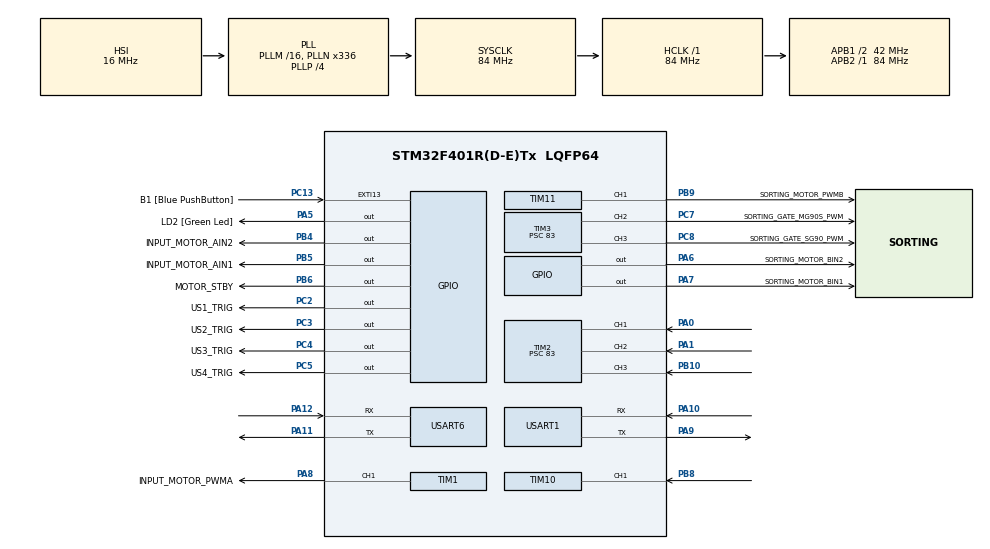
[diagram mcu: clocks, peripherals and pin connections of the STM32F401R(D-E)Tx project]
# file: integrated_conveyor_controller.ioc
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Dma.Request0=USART1_RX
Dma.Request1=USART1_TX
Dma.Request2=USART6_RX
Dma.Request3=USART6_TX
Dma.USART1_RX.0.Direction=DMA_PERIPH_TO_MEMORY
Dma.USART1_RX.0.FIFOMode=DMA_FIFOMODE_DISABLE
Dma.USART1_RX.0.Instance=DMA2_Stream5
Dma.USART1_RX.0.MemDataAlignment=DMA_MDATAALIGN_BYTE
Dma.USART1_RX.0.MemInc=DMA_MINC_ENABLE
Dma.USART1_RX.0.Mode=DMA_CIRCULAR
Dma.USART1_RX.0.PeriphDataAlignment=DMA_PDATAALIGN_BYTE
Dma.USART1_RX.0.PeriphInc=DMA_PINC_DISABLE
Dma.USART1_RX.0.Priority=DMA_PRIORITY_HIGH
Dma.USART1_TX.1.Direction=DMA_MEMORY_TO_PERIPH
Dma.USART1_TX.1.FIFOMode=DMA_FIFOMODE_DISABLE
Dma.USART1_TX.1.Instance=DMA2_Stream7
Dma.USART1_TX.1.MemDataAlignment=DMA_MDATAALIGN_BYTE
Dma.USART1_TX.1.MemInc=DMA_MINC_ENABLE
Dma.USART1_TX.1.Mode=DMA_NORMAL
Dma.USART1_TX.1.PeriphDataAlignment=DMA_PDATAALIGN_BYTE
Dma.USART1_TX.1.PeriphInc=DMA_PINC_DISABLE
Dma.USART1_TX.1.Priority=DMA_PRIORITY_MEDIUM
Dma.USART6_RX.2.Direction=DMA_PERIPH_TO_MEMORY
Dma.USART6_RX.2.FIFOMode=DMA_FIFOMODE_DISABLE
Dma.USART6_RX.2.Instance=DMA2_Stream1
Dma.USART6_RX.2.MemDataAlignment=DMA_MDATAALIGN_BYTE
Dma.USART6_RX.2.MemInc=DMA_MINC_ENABLE
Dma.USART6_RX.2.Mode=DMA_CIRCULAR
Dma.USART6_RX.2.PeriphDataAlignment=DMA_PDATAALIGN_BYTE
Dma.USART6_RX.2.PeriphInc=DMA_PINC_DISABLE
Dma.USART6_RX.2.Priority=DMA_PRIORITY_HIGH
Dma.USART6_TX.3.Direction=DMA_MEMORY_TO_PERIPH
Dma.USART6_TX.3.FIFOMode=DMA_FIFOMODE_DISABLE
Dma.USART6_TX.3.Instance=DMA2_Stream6
Dma.USART6_TX.3.MemDataAlignment=DMA_MDATAALIGN_BYTE
Dma.USART6_TX.3.MemInc=DMA_MINC_ENABLE
Dma.USART6_TX.3.Mode=DMA_NORMAL
Dma.USART6_TX.3.PeriphDataAlignment=DMA_PDATAALIGN_BYTE
Dma.USART6_TX.3.PeriphInc=DMA_PINC_DISABLE
Dma.USART6_TX.3.Priority=DMA_PRIORITY_MEDIUM
FREERTOS.Tasks01=CommRxTask,32,512,StartCommRxTask,As weak,NULL,Dynamic,NULL,NULL;InputControlTask,24,512,StartInputControlTask,As weak,NULL,Dynamic,NULL,NULL;SortingControlTask,24,512,StartSortingControlTask,As weak,NULL,Dynamic,NULL,NULL;SafetyTask,40,512,StartSafetyTask,As weak,NULL,Dynamic,NULL,NULL;CommTxTask,32,512,StartCommTxTask,As weak,NULL,Dynamic,NULL,NULL;SensorTask,24,512,StartSensorTask,As weak,NULL,Dynamic,NULL,NULL;HealthTask,16,512,StartHealthTask,As weak,NULL,Dynamic,NULL,NULL
FREERTOS.configMAX_TASK_NAME_LEN=24
FREERTOS.configTOTAL_HEAP_SIZE=32768
Mcu.Family=STM32F4
Mcu.Name=STM32F401R(D-E)Tx
Mcu.Package=LQFP64
NVIC.DMA2_Stream1_IRQn=true\:5\:0\:false\:false\:true\:true\:false\:true\:true
NVIC.DMA2_Stream5_IRQn=true\:5\:0\:false\:false\:true\:true\:false\:true\:true
NVIC.DMA2_Stream6_IRQn=true\:6\:0\:true\:false\:true\:true\:false\:true\:true
NVIC.DMA2_Stream7_IRQn=true\:6\:0\:true\:false\:true\:true\:false\:true\:true
NVIC.PriorityGroup=NVIC_PRIORITYGROUP_4
NVIC.TIM1_UP_TIM10_IRQn=true\:5\:0\:false\:false\:true\:true\:true\:true\:true
NVIC.TIM2_IRQn=true\:5\:0\:false\:false\:true\:true\:true\:true\:true
NVIC.TIM5_IRQn=true\:0\:0\:false\:false\:true\:false\:false\:true\:true
NVIC.TimeBase=TIM5_IRQn
NVIC.TimeBaseIP=TIM5
NVIC.USART1_IRQn=true\:5\:0\:false\:false\:true\:true\:true\:true\:true
NVIC.USART6_IRQn=true\:5\:0\:false\:false\:true\:true\:true\:true\:true
PA0-WKUP.GPIO_PuPd=GPIO_PULLDOWN
PA0-WKUP.Signal=S_TIM2_CH1_ETR
PA1.GPIO_PuPd=GPIO_PULLDOWN
PA1.Signal=S_TIM2_CH2
PA10.Mode=Asynchronous
PA10.Signal=USART1_RX
PA11.Mode=Asynchronous
PA11.Signal=USART6_TX
PA12.Mode=Asynchronous
PA12.Signal=USART6_RX
PA13.GPIO_Label=TMS
PA13.Mode=Serial_Wire
PA13.Signal=SYS_JTMS-SWDIO
PA14.GPIO_Label=TCK
PA14.Mode=Serial_Wire
PA14.Signal=SYS_JTCK-SWCLK
PA5.GPIO_Label=LD2 [Green Led]
PA5.GPIO_Mode=GPIO_MODE_OUTPUT_PP
PA5.GPIO_PuPd=GPIO_NOPULL
PA5.GPIO_Speed=GPIO_SPEED_FREQ_LOW
PA5.Signal=GPIO_Output
PA6.GPIO_Label=SORTING_MOTOR_BIN2
PA6.Signal=GPIO_Output
PA7.GPIO_Label=SORTING_MOTOR_BIN1
PA7.Signal=GPIO_Output
PA8.GPIO_Label=INPUT_MOTOR_PWMA
PA8.Signal=S_TIM1_CH1
PA9.Mode=Asynchronous
PA9.Signal=USART1_TX
PB10.GPIO_PuPd=GPIO_PULLDOWN
PB10.Signal=S_TIM2_CH3
PB3.GPIO_Label=SWO
PB3.Signal=SYS_JTDO-SWO
PB4.GPIO_Label=INPUT_MOTOR_AIN2
PB4.Signal=GPIO_Output
PB5.GPIO_Label=INPUT_MOTOR_AIN1
PB5.Signal=GPIO_Output
PB6.GPIO_Label=MOTOR_STBY
PB6.Signal=GPIO_Output
PB8.GPIO_PuPd=GPIO_PULLDOWN
PB8.Signal=S_TIM10_CH1
PB9.GPIO_Label=SORTING_MOTOR_PWMB
PB9.Signal=S_TIM11_CH1
PC13-ANTI_TAMP.GPIO_Label=B1 [Blue PushButton]
PC13-ANTI_TAMP.GPIO_ModeDefaultEXTI=GPIO_MODE_IT_FALLING
PC13-ANTI_TAMP.GPIO_PuPd=GPIO_NOPULL
PC13-ANTI_TAMP.Signal=GPXTI13
PC14-OSC32_IN.Signal=RCC_OSC32_IN
PC15-OSC32_OUT.Signal=RCC_OSC32_OUT
PC2.GPIO_Label=US1_TRIG
PC2.Signal=GPIO_Output
PC3.GPIO_Label=US2_TRIG
PC3.Signal=GPIO_Output
PC4.GPIO_Label=US3_TRIG
PC4.Signal=GPIO_Output
PC5.GPIO_Label=US4_TRIG
PC5.Signal=GPIO_Output
PC7.GPIO_Label=SORTING_GATE_MG90S_PWM
PC7.Signal=S_TIM3_CH2
PC8.GPIO_Label=SORTING_GATE_SG90_PWM
PC8.Signal=S_TIM3_CH3
PH0\ -\ OSC_IN.Mode=HSE-External-Clock-Source
PH0\ -\ OSC_IN.Signal=RCC_OSC_IN
PH1\ -\ OSC_OUT.Mode=HSE-External-Clock-Source
PH1\ -\ OSC_OUT.Signal=RCC_OSC_OUT
ProjectManager.HeapSize=0x200
ProjectManager.StackSize=0x400
ProjectManager.TargetToolchain=STM32CubeIDE
RCC.AHBFreq_Value=84000000
RCC.APB1CLKDivider=RCC_HCLK_DIV2
RCC.APB1Freq_Value=42000000
RCC.APB1TimFreq_Value=84000000
RCC.APB2Freq_Value=84000000
RCC.APB2TimFreq_Value=84000000
RCC.CortexFreq_Value=84000000
RCC.HCLKFreq_Value=84000000
RCC.HSE_VALUE=8000000
RCC.HSI_VALUE=16000000
RCC.LSE_VALUE=32768
RCC.PLLN=336
RCC.PLLP=RCC_PLLP_DIV4
RCC.PLLQ=7
RCC.SYSCLKFreq_VALUE=84000000
RCC.SYSCLKSource=RCC_SYSCLKSOURCE_PLLCLK
RCC.VCOOutputFreq_Value=336000000
SH.S_TIM10_CH1.0=TIM10_CH1,Input_Capture1_from_TI1
SH.S_TIM11_CH1.0=TIM11_CH1,PWM Generation1 CH1
SH.S_TIM1_CH1.0=TIM1_CH1,PWM Generation1 CH1
SH.S_TIM2_CH1_ETR.0=TIM2_CH1,Input_Capture1_from_TI1
SH.S_TIM2_CH2.0=TIM2_CH2,Input_Capture2_from_TI2
SH.S_TIM2_CH3.0=TIM2_CH3,Input_Capture3_from_TI3
SH.S_TIM3_CH2.0=TIM3_CH2,PWM Generation2 CH2
SH.S_TIM3_CH3.0=TIM3_CH3,PWM Generation3 CH3
TIM1.Channel-PWM\ Generation1\ CH1=TIM_CHANNEL_1
TIM1.Period=4199
TIM10.Channel=TIM_CHANNEL_1
TIM10.Prescaler=83
TIM11.Channel=TIM_CHANNEL_1
TIM11.Period=4199
TIM2.Channel-Input_Capture1_from_TI1=TIM_CHANNEL_1
TIM2.Channel-Input_Capture2_from_TI2=TIM_CHANNEL_2
TIM2.Channel-Input_Capture3_from_TI3=TIM_CHANNEL_3
TIM2.Prescaler=83
TIM3.Channel-PWM\ Generation2\ CH2=TIM_CHANNEL_2
TIM3.Channel-PWM\ Generation3\ CH3=TIM_CHANNEL_3
TIM3.Period=19999
TIM3.Prescaler=83
USART1.VirtualMode=VM_ASYNC
USART6.VirtualMode=VM_ASYNC
VP_FREERTOS_VS_CMSIS_V2.Mode=CMSIS_V2
VP_SYS_VS_tim5.Mode=TIM5
VP_TIM10_VS_ClockSourceINT.Mode=Enable_Timer
VP_TIM11_VS_ClockSourceINT.Mode=Enable_Timer
board=NUCLEO-F401RE

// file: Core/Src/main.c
/* USER CODE BEGIN Header */
/**
  ******************************************************************************
  * @file           : main.c
  * @brief          : Main program body
  ******************************************************************************
  * @attention
  *
  * Copyright (c) 2026 STMicroelectronics.
  * All rights reserved.
  *
  * This software is licensed under terms that can be found in the LICENSE file
  * in the root directory of this software component.
  * If no LICENSE file comes with this software, it is provided AS-IS.
  *
  ******************************************************************************
  */
/* USER CODE END Header */
#include "main.h"
#include "cmsis_os.h"
#include "dma.h"
#include "tim.h"
#include "usart.h"
#include "gpio.h"

void SystemClock_Config(void);
void MX_FREERTOS_Init(void);

int main(void)
{

  /* MCU Configuration--------------------------------------------------------*/

  /* Reset of all peripherals, Initializes the Flash interface and the Systick. */
  HAL_Init();

  /* Configure the system clock */
  SystemClock_Config();

  /* Initialize all configured peripherals */
  MX_GPIO_Init();
  MX_DMA_Init();
  MX_USART1_UART_Init();
  MX_USART6_UART_Init();
  MX_TIM2_Init();
  MX_TIM10_Init();
  MX_TIM1_Init();
  MX_TIM3_Init();
  MX_TIM11_Init();

  /* Init scheduler */
  osKernelInitialize();  /* Call init function for freertos objects (in cmsis_os2.c) */
  MX_FREERTOS_Init();

  /* Start scheduler */
  osKernelStart();

  /* We should never get here as control is now taken by the scheduler */

  /* Infinite loop */
  while (1)
  {

  }
}

void SystemClock_Config(void)
{
  RCC_OscInitTypeDef RCC_OscInitStruct = {0};
  RCC_ClkInitTypeDef RCC_ClkInitStruct = {0};

  /** Configure the main internal regulator output voltage
  */
  __HAL_RCC_PWR_CLK_ENABLE();
  __HAL_PWR_VOLTAGESCALING_CONFIG(PWR_REGULATOR_VOLTAGE_SCALE2);

  /** Initializes the RCC Oscillators according to the specified parameters
  * in the RCC_OscInitTypeDef structure.
  */
  RCC_OscInitStruct.OscillatorType = RCC_OSCILLATORTYPE_HSI;
  RCC_OscInitStruct.HSIState = RCC_HSI_ON;
  RCC_OscInitStruct.HSICalibrationValue = RCC_HSICALIBRATION_DEFAULT;
  RCC_OscInitStruct.PLL.PLLState = RCC_PLL_ON;
  RCC_OscInitStruct.PLL.PLLSource = RCC_PLLSOURCE_HSI;
  RCC_OscInitStruct.PLL.PLLM = 16;
  RCC_OscInitStruct.PLL.PLLN = 336;
  RCC_OscInitStruct.PLL.PLLP = RCC_PLLP_DIV4;
  RCC_OscInitStruct.PLL.PLLQ = 7;
  if (HAL_RCC_OscConfig(&RCC_OscInitStruct) != HAL_OK)
  {
    Error_Handler();
  }

  /** Initializes the CPU, AHB and APB buses clocks
  */
  RCC_ClkInitStruct.ClockType = RCC_CLOCKTYPE_HCLK|RCC_CLOCKTYPE_SYSCLK
                              |RCC_CLOCKTYPE_PCLK1|RCC_CLOCKTYPE_PCLK2;
  RCC_ClkInitStruct.SYSCLKSource = RCC_SYSCLKSOURCE_PLLCLK;
  RCC_ClkInitStruct.AHBCLKDivider = RCC_SYSCLK_DIV1;
  RCC_ClkInitStruct.APB1CLKDivider = RCC_HCLK_DIV2;
  RCC_ClkInitStruct.APB2CLKDivider = RCC_HCLK_DIV1;

  if (HAL_RCC_ClockConfig(&RCC_ClkInitStruct, FLASH_LATENCY_2) != HAL_OK)
  {
    Error_Handler();
  }
}

void HAL_TIM_PeriodElapsedCallback(TIM_HandleTypeDef *htim)
{
  if (htim->Instance == TIM5)
  {
    HAL_IncTick();
  }
}

void Error_Handler(void)
{
  __disable_irq();
  while (1)
  {
  }
}

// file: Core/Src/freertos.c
/* USER CODE BEGIN Header */
/**
  ******************************************************************************
  * File Name          : freertos.c
  * Description        : Code for freertos applications
  ******************************************************************************
  * @attention
  *
  * Copyright (c) 2026 STMicroelectronics.
  * All rights reserved.
  *
  * This software is licensed under terms that can be found in the LICENSE file
  * in the root directory of this software component.
  * If no LICENSE file comes with this software, it is provided AS-IS.
  *
  ******************************************************************************
  */
/* USER CODE END Header */

#include "FreeRTOS.h"
#include "task.h"
#include "main.h"
#include "cmsis_os.h"

/* USER CODE BEGIN Includes */
#include "app_queues.h"
#include "fault_trap.h"
/* USER CODE END Includes */

/* Definitions for CommRxTask */
osThreadId_t CommRxTaskHandle;
const osThreadAttr_t CommRxTask_attributes = {
  .name = "CommRxTask",
  .stack_size = 512 * 4,
  .priority = (osPriority_t) osPriorityAboveNormal,
};
/* Definitions for InputControlTask */
osThreadId_t InputControlTaskHandle;
const osThreadAttr_t InputControlTask_attributes = {
  .name = "InputControlTask",
  .stack_size = 512 * 4,
  .priority = (osPriority_t) osPriorityNormal,
};
/* Definitions for SortingControlTask */
osThreadId_t SortingControlTaskHandle;
const osThreadAttr_t SortingControlTask_attributes = {
  .name = "SortingControlTask",
  .stack_size = 512 * 4,
  .priority = (osPriority_t) osPriorityNormal,
};
/* Definitions for SafetyTask */
osThreadId_t SafetyTaskHandle;
const osThreadAttr_t SafetyTask_attributes = {
  .name = "SafetyTask",
  .stack_size = 512 * 4,
  .priority = (osPriority_t) osPriorityHigh,
};
/* Definitions for CommTxTask */
osThreadId_t CommTxTaskHandle;
const osThreadAttr_t CommTxTask_attributes = {
  .name = "CommTxTask",
  .stack_size = 512 * 4,
  .priority = (osPriority_t) osPriorityAboveNormal,
};
/* Definitions for SensorTask */
osThreadId_t SensorTaskHandle;
const osThreadAttr_t SensorTask_attributes = {
  .name = "SensorTask",
  .stack_size = 512 * 4,
  .priority = (osPriority_t) osPriorityNormal,
};
/* Definitions for HealthTask */
osThreadId_t HealthTaskHandle;
const osThreadAttr_t HealthTask_attributes = {
  .name = "HealthTask",
  .stack_size = 512 * 4,
  .priority = (osPriority_t) osPriorityBelowNormal,
};

void StartCommRxTask(void *argument);
void StartInputControlTask(void *argument);
void StartSortingControlTask(void *argument);
void StartSafetyTask(void *argument);
void StartCommTxTask(void *argument);
void StartSensorTask(void *argument);
void StartHealthTask(void *argument);

void MX_FREERTOS_Init(void); /* (MISRA C 2004 rule 8.1) */

void MX_FREERTOS_Init(void) {

  /* USER CODE BEGIN RTOS_QUEUES */
  if (app_queues_init() != osOK)
  {
    Error_Handler();
  }
  /* add queues, ... */
  /* USER CODE END RTOS_QUEUES */

  /* Create the thread(s) */
  /* creation of CommRxTask */
  CommRxTaskHandle = osThreadNew(StartCommRxTask, NULL, &CommRxTask_attributes);

  /* creation of InputControlTask */
  InputControlTaskHandle = osThreadNew(StartInputControlTask, NULL, &InputControlTask_attributes);

  /* creation of SortingControlTask */
  SortingControlTaskHandle = osThreadNew(StartSortingControlTask, NULL, &SortingControlTask_attributes);

  /* creation of SafetyTask */
  SafetyTaskHandle = osThreadNew(StartSafetyTask, NULL, &SafetyTask_attributes);

  /* creation of CommTxTask */
  CommTxTaskHandle = osThreadNew(StartCommTxTask, NULL, &CommTxTask_attributes);

  /* creation of SensorTask */
  SensorTaskHandle = osThreadNew(StartSensorTask, NULL, &SensorTask_attributes);

  /* creation of HealthTask */
  HealthTaskHandle = osThreadNew(StartHealthTask, NULL, &HealthTask_attributes);

}

__weak void StartCommRxTask(void *argument)
{
  for(;;)
  {
    osDelay(1);
  }
}

__weak void StartInputControlTask(void *argument)
{
  for(;;)
  {
    osDelay(1);
  }
}

__weak void StartSortingControlTask(void *argument)
{
  for(;;)
  {
    osDelay(1);
  }
}

__weak void StartSafetyTask(void *argument)
{
  for(;;)
  {
    osDelay(1);
  }
}

__weak void StartCommTxTask(void *argument)
{
  for(;;)
  {
    osDelay(1);
  }
}

__weak void StartSensorTask(void *argument)
{
  for(;;)
  {
    osDelay(1);
  }
}

__weak void StartHealthTask(void *argument)
{
  for(;;)
  {
    osDelay(1);
  }
}

/* USER CODE BEGIN Application */

/*
 * 스택 오버플로 훅(configCHECK_FOR_STACK_OVERFLOW=2).
 *
 * FreeRTOS는 이 훅에서 돌아오는 것을 기대하지 않는다. 어느 태스크가 넘쳤는지
 * .noinit에 남기고 멈추면, IWDG가 리셋한 뒤에도 태스크 이름이 남는다.
 * 검사가 꺼져 있던 동안에는 넘친 태스크가 남의 메모리를 조용히 망가뜨리다
 * 한참 뒤 엉뚱한 곳에서 HardFault로 터졌을 것이다.
 */
void vApplicationStackOverflowHook(TaskHandle_t xTask, char *pcTaskName)
{
  (void)xTask;

  FaultTrap_CaptureTask(FAULT_TRAP_STACK_OVERFLOW, pcTaskName);

  taskDISABLE_INTERRUPTS();
  for (;;)
  {
  }
}

/* 힙 할당 실패 훅(configUSE_MALLOC_FAILED_HOOK=1). 같은 이유로 기록 후 정지한다.
 * 태스크 이름은 남기지 않는다 - pcTaskGetName()은 INCLUDE_pcTaskGetTaskName이
 * 필요한데, 그 정의는 CubeMX가 관리하는 영역이라 .ioc 재생성 때 사라지면
 * 링크가 깨진다. 힙 고갈은 대개 초기화 중에 나므로 종류만으로도 충분하다. */
void vApplicationMallocFailedHook(void)
{
  FaultTrap_CaptureTask(FAULT_TRAP_MALLOC_FAILED, NULL);

  taskDISABLE_INTERRUPTS();
  for (;;)
  {
  }
}

/* USER CODE END Application */
